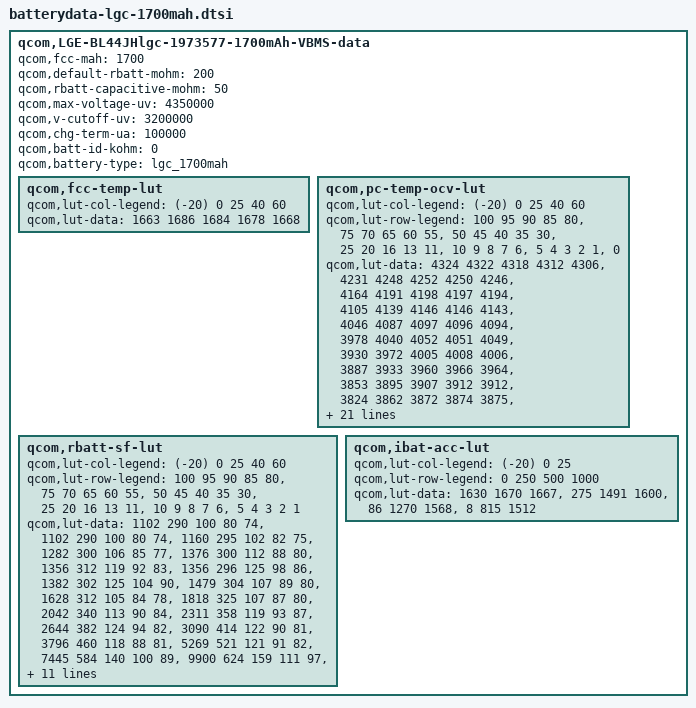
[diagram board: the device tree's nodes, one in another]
/* Copyright (c) 2013-2014, The Linux Foundation. All rights reserved.
 *
 * This program is free software; you can redistribute it and/or modify
 * it under the terms of the GNU General Public License version 2 and
 * only version 2 as published by the Free Software Foundation.
 *
 * This program is distributed in the hope that it will be useful,
 * but WITHOUT ANY WARRANTY; without even the implied warranty of
 * MERCHANTABILITY or FITNESS FOR A PARTICULAR PURPOSE.  See the
 * GNU General Public License for more details.
 */

qcom,LGE-BL44JHlgc-1973577-1700mAh-VBMS-data {
	qcom,fcc-mah = <1700>;
	qcom,default-rbatt-mohm = <200>;
	qcom,rbatt-capacitive-mohm = <50>;
	qcom,max-voltage-uv = <4350000>;
	qcom,v-cutoff-uv = <3200000>;
	qcom,chg-term-ua = <100000>;
	qcom,batt-id-kohm = <0>;
	qcom,battery-type = "lgc_1700mah";

	qcom,fcc-temp-lut {
		qcom,lut-col-legend = <(-20) 0 25 40 60>;
		qcom,lut-data = <1663 1686 1684 1678 1668>;
	};

	qcom,pc-temp-ocv-lut {
		qcom,lut-col-legend = <(-20) 0 25 40 60>;
		qcom,lut-row-legend = <100 95 90 85 80>,
				<75 70 65 60 55>,
				<50 45 40 35 30>,
				<25 20 16 13 11>,
				<10 9 8 7 6>,
				<5 4 3 2 1>,
				<0>;
		qcom,lut-data = <4324 4322 4318 4312 4306>,
				<4231 4248 4252 4250 4246>,
				<4164 4191 4198 4197 4194>,
				<4105 4139 4146 4146 4143>,
				<4046 4087 4097 4096 4094>,
				<3978 4040 4052 4051 4049>,
				<3930 3972 4005 4008 4006>,
				<3887 3933 3960 3966 3964>,
				<3853 3895 3907 3912 3912>,
				<3824 3862 3872 3874 3875>,
				<3800 3832 3844 3847 3848>,
				<3776 3806 3822 3823 3824>,
				<3753 3782 3801 3802 3802>,
				<3730 3763 3783 3779 3771>,
				<3702 3744 3756 3750 3739>,
				<3666 3726 3716 3710 3698>,
				<3610 3704 3692 3685 3675>,
				<3544 3684 3681 3671 3656>,
				<3478 3639 3644 3638 3622>,
				<3428 3592 3606 3601 3584>,
				<3400 3564 3584 3578 3560>,
				<3374 3534 3555 3549 3533>,
				<3344 3502 3523 3518 3502>,
				<3318 3466 3490 3486 3472>,
				<3289 3429 3458 3456 3443>,
				<3270 3393 3426 3424 3410>,
				<3248 3354 3387 3385 3371>,
				<3222 3308 3339 3335 3320>,
				<3186 3252 3274 3267 3248>,
				<3113 3166 3178 3166 3145>,
				<3000 3000 3000 3000 3000>;
	};

	qcom,rbatt-sf-lut {
		qcom,lut-col-legend = <(-20) 0 25 40 60>;
		qcom,lut-row-legend = <100 95 90 85 80>,
				<75 70 65 60 55>,
				<50 45 40 35 30>,
				<25 20 16 13 11>,
				<10 9 8 7 6>,
				<5 4 3 2 1>;
		qcom,lut-data = <1102 290 100 80 74>,
				<1102 290 100 80 74>,
				<1160 295 102 82 75>,
				<1282 300 106 85 77>,
				<1376 300 112 88 80>,
				<1356 312 119 92 83>,
				<1356 296 125 98 86>,
				<1382 302 125 104 90>,
				<1479 304 107 89 80>,
				<1628 312 105 84 78>,
				<1818 325 107 87 80>,
				<2042 340 113 90 84>,
				<2311 358 119 93 87>,
				<2644 382 124 94 82>,
				<3090 414 122 90 81>,
				<3796 460 118 88 81>,
				<5269 521 121 91 82>,
				<7445 584 140 100 89>,
				<9900 624 159 111 97>,
				<11967 646 172 118 102>,
				<13361 639 175 121 105>,
				<14713 612 166 122 108>,
				<15458 645 174 127 112>,
				<17998 684 187 136 117>,
				<20910 736 206 146 124>,
				<24756 832 228 158 130>,
				<30631 1087 250 172 138>,
				<38503 1556 283 189 151>,
				<49248 2298 358 224 176>,
				<56740 3912 529 312 258>;
	};

	qcom,ibat-acc-lut {
		qcom,lut-col-legend = <(-20) 0 25>;
		qcom,lut-row-legend = <0 250 500 1000>;
		qcom,lut-data = <1630 1670 1667>,
				<275 1491 1600>,
				<86 1270 1568>,
				<8 815 1512>;
	};
};
